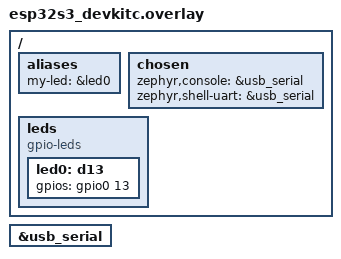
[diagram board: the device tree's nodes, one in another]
/ {
    aliases {
        my-led = &led0;
    };

    chosen {
        zephyr,console = &usb_serial;
        zephyr,shell-uart = &usb_serial;
    };

    leds {
        compatible = "gpio-leds";
        led0: d13 {
            gpios = <&gpio0 13 GPIO_ACTIVE_HIGH>;
        };
    };
};

&usb_serial {
    status = "okay";
};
